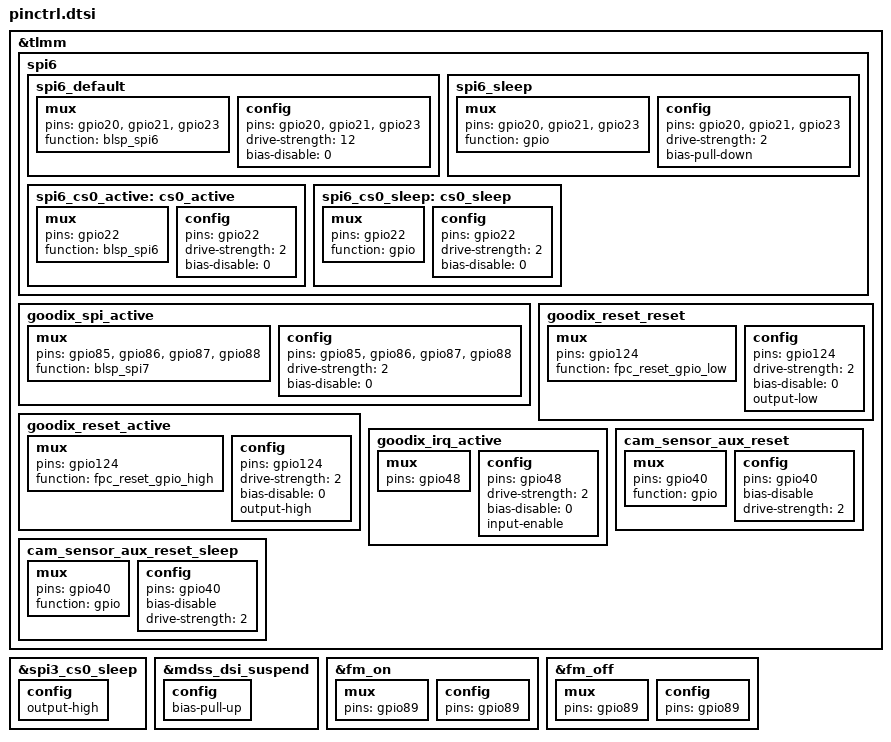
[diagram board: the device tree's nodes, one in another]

&tlmm {
	/delete-node/ i2c_4;

	spi6 {
		spi6_default: spi6_default {
			/* active state */
			mux {
				/* MOSI, MISO, CLK */
				pins = "gpio20", "gpio21", "gpio23";
				function = "blsp_spi6";
			};

			config {
				pins = "gpio20", "gpio21", "gpio23";
				drive-strength = <12>; /* 12 MA */
				bias-disable = <0>; /* No PULL */
			};
		};

		spi6_sleep: spi6_sleep {
			/* suspended state */
			mux {
				/* MOSI, MISO, CLK */
				pins = "gpio20", "gpio21", "gpio23";
				function = "gpio";
			};

			config {
				pins = "gpio20", "gpio21", "gpio23";
				drive-strength = <2>; /* 2 MA */
				bias-pull-down; /* PULL Down */
			};
		};

		spi6_cs0_active: cs0_active {
			/* CS */
			mux {
				pins = "gpio22";
				function = "blsp_spi6";
			};

			config {
				pins = "gpio22";
				drive-strength = <2>;
				bias-disable = <0>;
			};
		};

		spi6_cs0_sleep: cs0_sleep {
			/* CS */
			mux {
				pins = "gpio22";
				function = "gpio";
			};

			config {
				pins = "gpio22";
				drive-strength = <2>;
				bias-disable = <0>;
			};
		};
	};

	/*add fingerprint for C3I-224 by gaoge start*/
	goodix_spi_active: goodix_spi_active{
		mux {
			pins = "gpio85", "gpio86", "gpio87", "gpio88";
			function = "blsp_spi7";
		};
		config {
			pins = "gpio85", "gpio86", "gpio87", "gpio88";
			drive-strength = <2>;
			bias-disable = <0>;
		};
	};
	goodix_reset_reset: goodix_reset_reset{
		mux {
			pins = "gpio124";
			function = "fpc_reset_gpio_low";
		};
		config {
			pins = "gpio124";
			drive-strength = <2>;
			bias-disable = <0>;
			output-low;
		};
	};
	goodix_reset_active: goodix_reset_active{
		mux {
			pins = "gpio124";
			function = "fpc_reset_gpio_high";
		};
		config {
			pins = "gpio124";
			drive-strength = <2>;
			bias-disable = <0>;
			output-high;
		};
	};
	goodix_irq_active: goodix_irq_active {
		mux {
			pins = "gpio48";
			/*function = "gpio";*/
		};
		config {
			pins = "gpio48";
			drive-strength = <2>;
			bias-disable = <0>;
			input-enable;
		};
	};
	/*add fingerprint for C3I-224 by gaoge end*/

	/delete-node/ pmx_quat_mi2s;
	/delete-node/ pmx_quat_mi2s_din;
	/delete-node/ cdc-dmic-lines;

	cam_sensor_aux_reset: cam_sensor_aux_reset {
		/* RESET */
		mux {
			pins = "gpio40";
			function = "gpio";
		};

		config {
		pins = "gpio40";
			bias-disable; /* No PULL */
			drive-strength = <2>; /* 2 MA */
		};
	};

	cam_sensor_aux_reset_sleep: cam_sensor_aux_reset_sleep {
		/* RESET */
		mux {
			pins = "gpio40";
			function = "gpio";
		};

		config {
			pins = "gpio40";
			bias-disable; /* No PULL */
			drive-strength = <2>; /* 2 MA */
		};
	};
};

&spi3_cs0_sleep {
	config {
		/delete-property/ bias-disable;
		output-high;
	};
};

&mdss_dsi_suspend {
	config {
		/delete-property/ bias-pull-down;
		bias-pull-up;
	};
};

&fm_on {
	mux {
		pins = "gpio89";
	};
	config {
		pins = "gpio89";
	};
};

&fm_off {
	mux {
		pins = "gpio89";
	};
	config {
		pins = "gpio89";
	};
};
